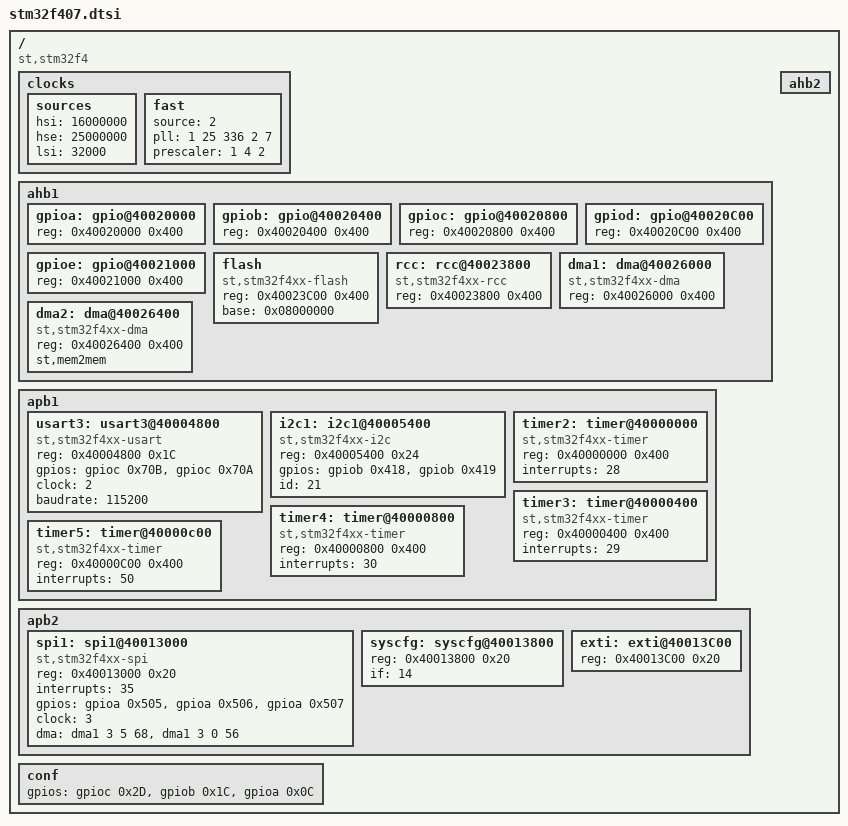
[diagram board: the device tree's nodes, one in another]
/ {
    compatible = "st,stm32f4";

    #address-cells = <1>;
    #size-cells = <1>;

	clocks
	{
		sources
		{
			hsi = <16000000>;
			hse = <25000000>;
			lsi = <32000>;
		};

		fast
		{
			source = <2>;			// hse is source
			pll = <1 25 336 2 7>;		// hsi, m, n, p, q
			prescaler = <1 4 2>;		// ahb div1, apb1&apb2 div=2
		};
	};

	ahb1
	{
		#address-cells = <1>;
		#size-cells = <1>;

		gpioa: gpio@40020000 {
			reg = <0x40020000 0x400>;
                        status = "okay";
		};

		gpiob: gpio@40020400 {
			reg = <0x40020400 0x400>;
                        status = "okay";
		};

		gpioc: gpio@40020800 {
			reg = <0x40020800 0x400>;
                        status = "okay";
		};

		gpiod: gpio@40020C00 {
			reg = <0x40020C00 0x400>;
                        status = "okay";
		};

		gpioe: gpio@40021000 {
			reg = <0x40021000 0x400>;
                        status = "okay";
		};

		flash {
			#address-cells = <1>;
			#size-cells = <0>;
			compatible = "st,stm32f4xx-flash";
			reg = <0x40023C00 0x400>;
			base = <0x08000000>;
                        status = "okay";
		};

		rcc: rcc@40023800 {
			#clock-cells = <2>;
			reg = <0x40023800 0x400>;
			compatible = "st,stm32f4xx-rcc";
                        status = "okay";
		};

		dma1: dma@40026000 {
			reg = <0x40026000 0x400>;
			compatible = "st,stm32f4xx-dma";
		};

		dma2: dma@40026400 {
			reg = <0x40026400 0x400>;
			compatible = "st,stm32f4xx-dma";
			st,mem2mem;
		};
	};

	ahb2
	{

	};

	apb1
	{
		#address-cells = <1>;
		#size-cells = <1>;

		usart3: usart3@40004800 {
			compatible = "st,stm32f4xx-usart";
			reg = <0x40004800 0x1C>;
			gpios = <&gpioc 0x70B 0>,     /* TX PA2 */
				<&gpioc 0x70A 0>;     /* RX PA3 */
			clock = <2>;
			baudrate = <115200>;
                        status = "okay";
		};

		i2c1: i2c1@40005400 {
			#address-cells = <1>;
			#size-cells = <0>;
			compatible = "st,stm32f4xx-i2c";
			reg = <0x40005400 0x24>;
			gpios = <&gpiob 0x418 0x0E>,    /* SCL PB8 */
					<&gpiob 0x419 0x0E>;    /* SDA PB9 */
			id = <21>;
		};


                timer2: timer@40000000 {
                        compatible = "st,stm32f4xx-timer";
                        reg = <0x40000000 0x400>;
                        interrupts = <28>;
                        status = "okay";
                };

                timer3: timer@40000400 {
                        compatible = "st,stm32f4xx-timer";
                        reg = <0x40000400 0x400>;
                        interrupts = <29>;
                        status = "okay";
                };

                timer4: timer@40000800 {
                        compatible = "st,stm32f4xx-timer";
                        reg = <0x40000800 0x400>;
                        interrupts = <30>;
                        status = "okay";
                };

                timer5: timer@40000c00 {
                        compatible = "st,stm32f4xx-timer";
                        reg = <0x40000C00 0x400>;
                        interrupts = <50>;
                        status = "okay";
                };
	};

	apb2
	{
		#address-cells = <1>;
		#size-cells = <1>;

		spi1: spi1@40013000 {
			#address-cells = <1>;
			#size-cells = <0>;
			compatible = "st,stm32f4xx-spi";
			reg = <0x40013000 0x20>;
                        interrupts = <35>;
			gpios =	<&gpioa 0x505 0x0A>,     /* SCK, PA5 */
					<&gpioa 0x506 0x08>,     /* MISO PA6 */
					<&gpioa 0x507 0x0A>;     /* MOSI PA7 */
			clock = <3>;
			dma = <&dma1 3 5 68>, // tx
				<&dma1 3 0 56>; // rx
		};

		syscfg: syscfg@40013800 {
			reg = <0x40013800 0x20>;
			if = <14>;
		};

		exti: exti@40013C00 {
			reg = <0x40013C00 0x20>;
		};
	};

	conf
	{
		gpios =	<&gpioc 0x2D 0x20>,     /* IRQ PC13, input with pullup */
				<&gpiob 0x1C 0x20>,     /* NCS PB12 */
				<&gpioa 0x0C 0x20>;     /* DP PA12 */
	};
};
